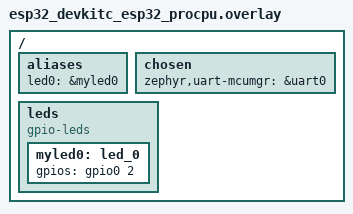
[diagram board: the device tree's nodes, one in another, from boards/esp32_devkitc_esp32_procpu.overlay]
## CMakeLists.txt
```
cmake_minimum_required(VERSION 3.20.0)

find_package(Zephyr REQUIRED HINTS $ENV{ZEPHYR_BASE})
project(example-app)

target_sources(app PRIVATE src/main.c)
```

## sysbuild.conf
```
SB_CONFIG_BOOTLOADER_MCUBOOT=y
SB_CONFIG_BOOT_SIGNATURE_TYPE_RSA=y
SB_CONFIG_BOOT_SIGNATURE_KEY_FILE="/Users/kapil.sachdeva/Desktop/Dev/myoss/zephyr-upgrade-mcumgr/assets/bootloader-key.pem"
```

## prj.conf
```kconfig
CONFIG_GPIO=y

CONFIG_LOG=y
CONFIG_LOG_MODE_DEFERRED=n
CONFIG_LOG_MODE_IMMEDIATE=y
CONFIG_LOG_DEFAULT_LEVEL=3

# Direct dependencies of MCUMGR
CONFIG_NET_BUF=y
CONFIG_ZCBOR=y

CONFIG_MCUMGR=y

# This enables image management commands
CONFIG_FLASH=y
CONFIG_FLASH_MAP=y
CONFIG_STREAM_FLASH=y
CONFIG_IMG_MANAGER=y
CONFIG_MCUMGR_GRP_IMG=y

# we need to turn this ON otherwise smpmgr fails on state-write
# confirmation
CONFIG_MCUMGR_GRP_OS=y

# Bootloader specific settings
CONFIG_BOOTLOADER_MCUBOOT=y
CONFIG_MCUBOOT_IMGTOOL_SIGN_VERSION="0.1.0+2"
```

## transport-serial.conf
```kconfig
# Deps of CONFIG_MCUMGR_TRANSPORT_UART
CONFIG_CONSOLE=y
CONFIG_BASE64=y
CONFIG_CRC=y

CONFIG_MCUMGR_TRANSPORT_UART=y
```

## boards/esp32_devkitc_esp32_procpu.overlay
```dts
/ {
        aliases {
	        led0 = &myled0;
        };

        chosen {
                zephyr,uart-mcumgr = &uart0;
        };

        leds {
                compatible = "gpio-leds";

                myled0: led_0 {
                        gpios = <&gpio0 2 GPIO_ACTIVE_HIGH>;
                };
        };
};
```

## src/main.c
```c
#include <stdio.h>
#include <zephyr/drivers/gpio.h>
#include <zephyr/kernel.h>
#include <zephyr/logging/log.h>

LOG_MODULE_REGISTER(main);

#define LED0_NODE DT_ALIAS(led0)

#define VERSION_STRING CONFIG_MCUBOOT_IMGTOOL_SIGN_VERSION

static const struct gpio_dt_spec led = GPIO_DT_SPEC_GET(LED0_NODE, gpios);

int main(void)
{
	int ret;
	bool led_state = true;

	printf("========\nVersion:  %s\n========\n\n", VERSION_STRING);

	if (!gpio_is_ready_dt(&led)) {
		LOG_ERR("Error, gpio is not ready\n");
		return 0;
	}

	ret = gpio_pin_configure_dt(&led, GPIO_OUTPUT_ACTIVE);
	if (ret < 0) {
		LOG_ERR("Error configuring gpio: %d\n", ret);
		return 0;
	}

	LOG_DBG("LED configured and ready to blink\n");
	while (1) {
		ret = gpio_pin_toggle_dt(&led);
		if (ret < 0) {
			LOG_ERR("Error toggling led\n");
			return 0;
		}

		led_state = !led_state;
		// printf("LED is now: %s\n", led_state ? "ON" : "OFF");

		k_msleep(1000);
	}
	return 0;
}
```
